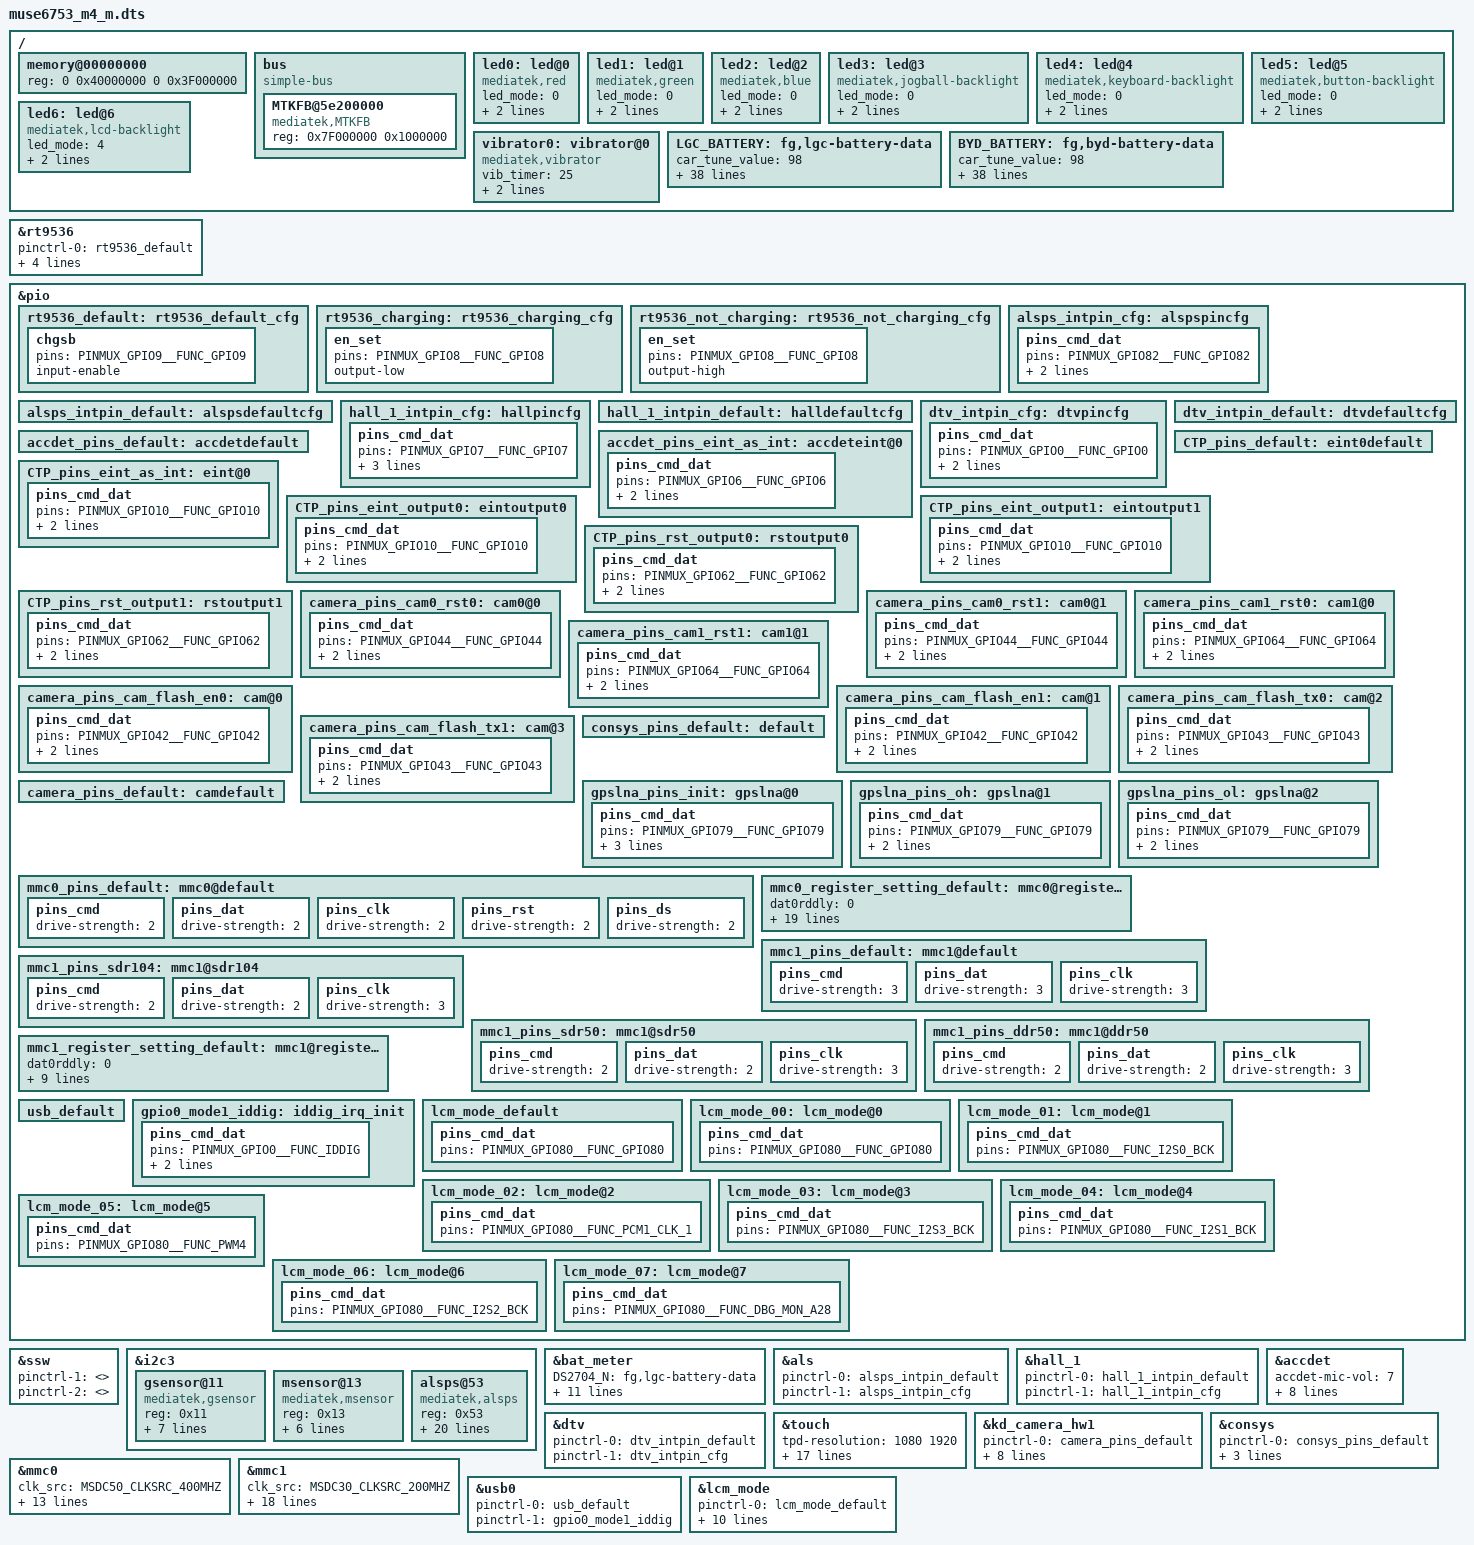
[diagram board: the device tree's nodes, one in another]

/dts-v1/;

#include "mt6753.dtsi"
#include <dt-bindings/lcm/r63417_fhd_dsi_cmd_truly_nt50358.dtsi>

/ {
memory@00000000 {
		device_type = "memory";
		reg = <0 0x40000000 0 0x3F000000>;
	};

	bus {
		compatible = "simple-bus";
		#address-cells = <1>;
		#size-cells = <1>;
		ranges = <0 0 0 0xffffffff>;

		MTKFB@5e200000 {
			compatible = "mediatek,MTKFB";
			reg = <0x7F000000 0x1000000>;
		};

	};
	led0:led@0 {
		compatible = "mediatek,red";
		led_mode = <0>;
		data = <1>;
		pwm_config = <0 0 0 0 0>;
	};
	led1:led@1 {
		compatible = "mediatek,green";
		led_mode = <0>;
		data = <1>;
		pwm_config = <0 0 0 0 0>;
	};
	led2:led@2 {
		compatible = "mediatek,blue";
		led_mode = <0>;
		data = <1>;
		pwm_config = <0 0 0 0 0>;
	};
	led3:led@3 {
		compatible = "mediatek,jogball-backlight";
		led_mode = <0>;
		data = <1>;
		pwm_config = <0 0 0 0 0>;
	};
	led4:led@4 {
		compatible = "mediatek,keyboard-backlight";
		led_mode = <0>;
		data = <1>;
		pwm_config = <0 0 0 0 0>;
	};
	led5:led@5 {
		compatible = "mediatek,button-backlight";
		led_mode = <0>;
		data = <1>;
		pwm_config = <0 0 0 0 0>;
	};
	led6:led@6 {
		compatible = "mediatek,lcd-backlight";
		led_mode = <4>;
		data = <1>;
		pwm_config = <0 0 0 0 0>;
	};
	vibrator0:vibrator@0 {
		compatible = "mediatek,vibrator";
		vib_timer = <25>;
		vib_limit = <9>;
		vib_vol= <6>;
	};
};

/* charger ic */
&rt9536 {
	status = "okay";
	pinctrl-names = "default", "charging", "not_charging";
	pinctrl-0 = <&rt9536_default>;
	pinctrl-1 = <&rt9536_charging>;
	pinctrl-2 = <&rt9536_not_charging>;
	en_set = <8>;
	chgsb = <9>;
};
&pio {
	rt9536_default: rt9536_default_cfg {
		chgsb {
			pins = <PINMUX_GPIO9__FUNC_GPIO9>;
			input-enable;
		};
	};

	rt9536_charging: rt9536_charging_cfg {
		en_set {
			pins = <PINMUX_GPIO8__FUNC_GPIO8>;
			output-low;
		};
	};
	rt9536_not_charging: rt9536_not_charging_cfg {
		en_set {
			pins = <PINMUX_GPIO8__FUNC_GPIO8>;
			output-high;
		};
	};
};

&ssw {
	pinctrl-1 = <>;
	pinctrl-2 = <>;
};
/* sensor standardization */
 &i2c3 {
	#address-cells = <1>;
	#size-cells = <0>;
	gsensor@11 {
		compatible = "mediatek,gsensor";
		reg = <0x11>;
		status = "okay";
		i2c_num				= <3>;
		i2c_addr				= <0x11 0 0 0>;
		direction				= <0>;
		power_id				= <0xffff>;
		power_vol				= <0>;
		firlen					= <0>;
		is_batch_supported			= <0>;
	};
	msensor@13 {
		compatible = "mediatek,msensor";
		reg = <0x13>;
		status = "okay";
		i2c_num				= <3>;
		i2c_addr				= <0x13 0 0 0>;
		direction				= <0>;
		power_id				= <0xffff>;
		power_vol				= <0>;
		is_batch_supported	= <0>;
	};
	alsps@53 {
		compatible = "mediatek,alsps";
		reg = <0x53>;
		status = "okay";
		i2c_num				= <3>;
		i2c_addr				= <0x53 0 0 0>;
		polling_mode_ps			= <0>;
		polling_mode_als		= <0>;
		power_id				= <0xffff>;
		power_vol				= <0>;
		als_level = <0 328 861 1377 3125 7721 7767 12621 23062 28430 33274 47116 57694 57694 65535>;
		als_value = <0 133 304 502 1004 2005 3058 5005 8008 10010 12000 16000 20000 20000 20000 20000>;
		near_offset		=  <200>;
		far_offset		=  <85>;
		crosstalk_max		=  <500>;
		ppcount			=  <50>;
		ps_led_current	=	<6>;/* 4:50mA  5:75mA  6:100mA */
		als_up_thres	=	<19>;
		als_low_thres	=	<15>;
		als_gain	=	<3>;
		is_batch_supported_ps	= <0>;
		is_batch_supported_als	= <0>;
	};
};

/* fuel gauge */
&bat_meter {
	    DS2704_N = "fg,lgc-battery-data";
		DS2704_L = "fg,lgc-battery-data";
		DS2704_C = "fg,lgc-battery-data";
		ISL6296_N = "fg,lgc-battery-data";
		ISL6296_L = "fg,lgc-battery-data";
		ISL6296_C = "fg,lgc-battery-data";
		RA4301_VC0 = "fg,byd-battery-data";
		RA4301_VC1 = "fg,lgc-battery-data";
		RA4301_VC2 = "fg,byd-battery-data";
		SW3800_VC0 = "fg,lgc-battery-data";
		SW3800_VC1 = "fg,byd-battery-data";
		SW3800_VC2 = "fg,lgc-battery-data";
};

/ {
	/* LGC 2300mA Battery 3.2V cut off */
	LGC_BATTERY: fg,lgc-battery-data {
		car_tune_value = <98 >;
		/* Qmax for 0mA */
		q_max_pos_50 = <2306 >;
		q_max_pos_25 = <2228 >;
		q_max_pos_0 = <1821 >;
		q_max_neg_10 = <1509 >;
		/* Qmax for 400mA, said high current */
		q_max_pos_50_h_current = <2286 >;
		q_max_pos_25_h_current = <2222 >;
		q_max_pos_0_h_current = <1792 >;
		q_max_neg_10_h_current = <1151>;

		battery_profile_t0_num = <92 >;
		battery_profile_t0 = <
			0 4306 	2 4285 	4 4267 	6 4249 	8 4232
			10 4215 	12 4196 	14 4175 	16 4151 	18 4120
			20 4095 	22 4075 	24 4057 	26 4036 	28 4017
			30 3998 	32 3981 	34 3965 	36 3949 	38 3935
			40 3923 	42 3914 	44 3903 	46 3894 	48 3883
			50 3874 	52 3865 	54 3857 	56 3849 	58 3842
			60 3834 	62 3827 	64 3819 	66 3811 	68 3804
			70 3794 	72 3785 	74 3776 	76 3766 	78 3756
			80 3746 	82 3738 	83 3730 	85 3724 	87 3718
			89 3712 	91 3707 	92 3703 	93 3699 	93 3696
			94 3694 	94 3690 	95 3687 	95 3685 	96 3682
			96 3680 	96 3678 	97 3677 	97 3674 	97 3672
			97 3671 	98 3669 	98 3666 	98 3665 	98 3663
			98 3661 	99 3659 	99 3658 	99 3656 	99 3655
			99 3653 	99 3652 	99 3650 	99 3649 	99 3648
			99 3647 	99 3645 	99 3645 	100 3643 	100 3642
			100 3640 	100 3639 	100 3638 	100 3637 	100 3636
			100 3634 	100 3634 	100 3633 	100 3632 	100 3632
			100 3630 	100 3300 >;

		battery_profile_t1_num = <92 >;
		battery_profile_t1 = <
			0 4326 	2 4297 	3 4257 	5 4228 	7 4209
			8 4191 	10 4176 	12 4160 	13 4145 	15 4130
			16 4116 	18 4101 	20 4088 	21 4077 	23 4063
			25 4046 	26 4028 	28 4010 	30 3992 	31 3975
			33 3959 	35 3945 	36 3932 	38 3922 	40 3912
			41 3903 	43 3893 	44 3885 	46 3875 	48 3867
			49 3860 	51 3852 	53 3845 	54 3838 	56 3832
			58 3825 	59 3819 	61 3813 	63 3807 	64 3802
			66 3795 	67 3789 	69 3782 	71 3775 	72 3768
			74 3760 	76 3754 	77 3746 	79 3738 	81 3730
			82 3721 	84 3714 	86 3708 	87 3704 	89 3701
			90 3696 	92 3689 	94 3674 	95 3644 	97 3590
			98 3550 	99 3523 	99 3505 	99 3493 	99 3483
			99 3476 	99 3470 	100 3466 	100 3462 	100 3459
			100 3456 	100 3455 	100 3452 	100 3452 	100 3451
			100 3450 	100 3449 	100 3447 	100 3446 	100 3444
			100 3443 	100 3442 	100 3441 	100 3440 	100 3439
			100 3437 	100 3435 	100 3435 	100 3433 	100 3432
			100 3432 	100 3300 >;

		battery_profile_t2_num = <92 >;
		battery_profile_t2 = <
			0 4334 	1 4310 	3 4291 	4 4274 	5 4258
			7 4242 	8 4227 	9 4212 	11 4196 	12 4181
			13 4167 	15 4153 	16 4139 	18 4125 	19 4111
			20 4097 	22 4084 	23 4073 	24 4066 	26 4054
			27 4033 	28 4011 	30 3996 	31 3987 	32 3981
			34 3974 	35 3964 	36 3954 	38 3943 	39 3932
			40 3919 	42 3906 	43 3891 	44 3879 	46 3869
			47 3860 	48 3852 	50 3844 	51 3837 	53 3831
			54 3825 	55 3820 	57 3815 	58 3810 	59 3805
			61 3801 	62 3797 	63 3793 	65 3789 	66 3786
			67 3782 	69 3778 	70 3775 	71 3771 	73 3767
			74 3762 	75 3757 	77 3751 	78 3747 	79 3742
			81 3736 	82 3728 	83 3720 	85 3712 	86 3701
			87 3693 	89 3691 	90 3689 	92 3688 	93 3685
			94 3670 	96 3620 	97 3548 	98 3443 	100 3249
			100 3048 	100 2984 	100 2957 	100 2946 	100 2934
			100 2928 	100 2922 	100 2919 	100 2916 	100 2912
			100 2912 	100 2912 	100 2912 	100 2912 	100 2912
			100 2912 	100 2912 >;

		battery_profile_t3_num = <92 >;
		battery_profile_t3 = <
			0 4339 	1 4318 	3 4299 	4 4282 	5 4265
			7 4249 	8 4234 	9 4217 	10 4203 	12 4186
			13 4172 	14 4157 	16 4142 	17 4128 	18 4115
			20 4101 	21 4087 	22 4074 	23 4062 	25 4049
			26 4035 	27 4022 	29 4009 	30 3997 	31 3987
			32 3978 	34 3967 	35 3957 	36 3947 	38 3938
			39 3927 	40 3916 	42 3905 	43 3890 	44 3878
			45 3865 	47 3855 	48 3846 	49 3839 	51 3832
			52 3825 	53 3820 	55 3814 	56 3809 	57 3804
			58 3799 	60 3795 	61 3791 	62 3787 	64 3784
			65 3781 	66 3778 	68 3775 	69 3771 	70 3769
			71 3765 	73 3761 	74 3756 	75 3751 	77 3746
			78 3740 	79 3736 	81 3731 	82 3721 	83 3712
			84 3703 	86 3692 	87 3682 	88 3679 	90 3675
			91 3671 	92 3665 	93 3649 	95 3602 	96 3533
			97 3434 	98 3316 	100 3291 	100 3279 	100 3273
			100 3268 	100 3264 	100 3264 	100 3262 	100 3259
			100 3257 	100 3258 	100 3260 	100 3261 	100 3261
			100 3261 	100 3261 >;

		battery_profile_temperature_num = <92 >;
		battery_profile_temperature = <
			0 0 	0 0 	0 0 	0 0 	0 0
			0 0 	0 0 	0 0 	0 0 	0 0
			0 0 	0 0 	0 0 	0 0 	0 0
			0 0 	0 0 	0 0 	0 0 	0 0
			0 0 	0 0 	0 0 	0 0 	0 0
			0 0 	0 0 	0 0 	0 0 	0 0
			0 0 	0 0 	0 0 	0 0 	0 0
			0 0 	0 0 	0 0 	0 0 	0 0
			0 0 	0 0 	0 0 	0 0 	0 0
			0 0 	0 0 	0 0 	0 0 	0 0
			0 0 	0 0 	0 0 	0 0 	0 0
			0 0 	0 0 	0 0 	0 0 	0 0
			0 0 	0 0 	0 0 	0 0 	0 0
			0 0 	0 0 	0 0 	0 0 	0 0
			0 0 	0 0 	0 0 	0 0 	0 0
			0 0 	0 0 	0 0 	0 0 	0 0
			0 0 	0 0 	0 0 	0 0 	0 0
			0 0 	0 0 	0 0 	0 0 	0 0
			0 0 	0 0 >;

		r_profile_t0_num = <92 >;
		r_profile_t0 = <
			638 4306 	638 4285 	660 4267 	670 4249 	683 4232
			698 4215 	708 4196 	725 4175 	748 4151 	825 4120
			933 4095 	988 4075 	1030 4057 	1043 4036 	1048 4017
			1050 3998 	1048 3981 	1048 3965 	1040 3949 	1038 3935
			1043 3923 	1048 3914 	1055 3903 	1063 3894 	1063 3883
			1070 3874 	1073 3865 	1083 3857 	1088 3849 	1098 3842
			1105 3834 	1113 3827 	1118 3819 	1125 3811 	1133 3804
			1138 3794 	1145 3785 	1153 3776 	1158 3766 	1165 3756
			1173 3746 	1188 3738 	1208 3730 	1233 3724 	1260 3718
			1283 3712 	1270 3707 	1258 3703 	1248 3699 	1240 3696
			1235 3694 	1225 3690 	1220 3687 	1213 3685 	1205 3682
			1200 3680 	1195 3678 	1193 3677 	1188 3674 	1183 3672
			1178 3671 	1175 3669 	1168 3666 	1165 3665 	1160 3663
			1155 3661 	1148 3659 	1148 3658 	1145 3656 	1143 3655
			1138 3653 	1138 3652 	1128 3650 	1125 3649 	1123 3648
			1118 3647 	1115 3645 	1118 3645 	1113 3643 	1110 3642
			1108 3640 	1103 3639 	1103 3638 	1098 3637 	1098 3636
			1098 3634 	1090 3634 	1090 3633 	1093 3632 	1090 3632
			1075 3630 	510 3300 >;

		r_profile_t1_num = <92 >;
		r_profile_t1 = <
			353 4326 	353 4297 	383 4257 	443 4228 	463 4209
			470 4191 	478 4176 	485 4160 	493 4145 	498 4130
			505 4116 	505 4101 	510 4088 	525 4077 	545 4063
			553 4046 	550 4028 	543 4010 	533 3992 	523 3975
			510 3959 	505 3945 	498 3932 	500 3922 	503 3912
			505 3903 	508 3893 	513 3885 	513 3875 	515 3867
			518 3860 	523 3852 	530 3845 	533 3838 	538 3832
			538 3825 	545 3819 	550 3813 	555 3807 	560 3802
			563 3795 	568 3789 	570 3782 	573 3775 	580 3768
			583 3760 	595 3754 	598 3746 	610 3738 	618 3730
			628 3721 	638 3714 	655 3708 	680 3704 	713 3701
			750 3696 	800 3689 	855 3674 	893 3644 	923 3590
			875 3550 	808 3523 	765 3505 	733 3493 	710 3483
			695 3476 	678 3470 	665 3466 	655 3462 	650 3459
			643 3456 	643 3455 	640 3452 	635 3452 	633 3451
			630 3450 	630 3449 	623 3447 	618 3446 	625 3444
			613 3443 	618 3442 	610 3441 	618 3440 	620 3439
			620 3437 	623 3435 	615 3435 	613 3433 	593 3432
			583 3432 	500 3300 >;

		r_profile_t2_num = <92 >;
		r_profile_t2 = <
			170 4334 	170 4310 	170 4291 	170 4274 	173 4258
			173 4242 	175 4227 	173 4212 	175 4196 	173 4181
			175 4167 	178 4153 	180 4139 	183 4125 	183 4111
			183 4097 	188 4084 	190 4073 	198 4066 	200 4054
			198 4033 	198 4011 	198 3996 	203 3987 	210 3981
			210 3974 	213 3964 	213 3954 	215 3943 	215 3932
			208 3919 	203 3906 	190 3891 	185 3879 	180 3869
			178 3860 	178 3852 	175 3844 	175 3837 	175 3831
			175 3825 	178 3820 	180 3815 	180 3810 	180 3805
			183 3801 	185 3797 	183 3793 	185 3789 	188 3786
			185 3782 	188 3778 	188 3775 	188 3771 	188 3767
			185 3762 	180 3757 	180 3751 	183 3747 	185 3742
			188 3736 	185 3728 	188 3720 	190 3712 	185 3701
			178 3693 	180 3691 	185 3689 	195 3688 	208 3685
			218 3670 	208 3620 	220 3548 	243 3443 	320 3249
			630 3048 	470 2984 	415 2957 	378 2946 	385 2934
			335 2928 	360 2922 	313 2919 	303 2916 	313 2912
			313 2912 	313 2912 	313 2912 	313 2912 	313 2912
			313 2912 	313 2912 >;

		r_profile_t3_num = <92 >;
		r_profile_t3 = <
			143 4339 	143 4318 	143 4299 	145 4282 	140 4265
			143 4249 	145 4234 	143 4217 	145 4203 	143 4186
			145 4172 	145 4157 	145 4142 	148 4128 	160 4115
			165 4101 	170 4087 	170 4074 	175 4062 	178 4049
			175 4035 	183 4022 	183 4009 	183 3997 	188 3987
			195 3978 	195 3967 	200 3957 	200 3947 	203 3938
			203 3927 	200 3916 	198 3905 	185 3890 	175 3878
			165 3865 	160 3855 	155 3846 	155 3839 	158 3832
			153 3825 	155 3820 	155 3814 	158 3809 	158 3804
			158 3799 	158 3795 	160 3791 	163 3787 	163 3784
			168 3781 	178 3778 	178 3775 	173 3771 	178 3769
			175 3765 	173 3761 	173 3756 	173 3751 	178 3746
			178 3740 	183 3736 	193 3731 	193 3721 	195 3712
			200 3703 	203 3692 	200 3682 	205 3679 	210 3675
			213 3671 	218 3665 	225 3649 	223 3602 	235 3533
			260 3434 	295 3316 	233 3291 	200 3279 	183 3273
			173 3268 	160 3264 	163 3264 	160 3262 	155 3259
			150 3257 	150 3258 	155 3260 	168 3261 	175 3261
			168 3261 	185 3261 >;

		r_profile_temperature_num = <92 >;
		r_profile_temperature = <
			0 0 	0 0 	0 0 	0 0 	0 0
			0 0 	0 0 	0 0 	0 0 	0 0
			0 0 	0 0 	0 0 	0 0 	0 0
			0 0 	0 0 	0 0 	0 0 	0 0
			0 0 	0 0 	0 0 	0 0 	0 0
			0 0 	0 0 	0 0 	0 0 	0 0
			0 0 	0 0 	0 0 	0 0 	0 0
			0 0 	0 0 	0 0 	0 0 	0 0
			0 0 	0 0 	0 0 	0 0 	0 0
			0 0 	0 0 	0 0 	0 0 	0 0
			0 0 	0 0 	0 0 	0 0 	0 0
			0 0 	0 0 	0 0 	0 0 	0 0
			0 0 	0 0 	0 0 	0 0 	0 0
			0 0 	0 0 	0 0 	0 0 	0 0
			0 0 	0 0 	0 0 	0 0 	0 0
			0 0 	0 0 	0 0 	0 0 	0 0
			0 0 	0 0 	0 0 	0 0 	0 0
			0 0 	0 0 	0 0 	0 0 	0 0
			0 0 	0 0 >;
	};

	/* BYD 2300mA Battery 3.3V cut off */
	BYD_BATTERY: fg,byd-battery-data {
		car_tune_value = <98 >;
		/* Qmax for 0mA */
		q_max_pos_50 = <2321 >;
		q_max_pos_25 = <2280 >;
		q_max_pos_0 = <2009 >;
		q_max_neg_10 = <1583 >;
		/* Qmax for 400mA, said high current */
		q_max_pos_50_h_current = <2294 >;
		q_max_pos_25_h_current = <2238 >;
		q_max_pos_0_h_current = <1674 >;
		q_max_neg_10_h_current = <1204 >;

		battery_profile_t0_num = <92 >;
		battery_profile_t0 = <
			0 4297 	2 4270 	4 4246 	6 4221 	8 4188
			9 4151 	11 4125 	13 4107 	15 4095 	17 4081
			19 4065 	21 4047 	23 4028 	25 4010 	26 3994
			28 3980 	30 3967 	32 3956 	34 3945 	36 3932
			38 3918 	40 3904 	42 3891 	44 3878 	45 3867
			47 3856 	49 3847 	51 3838 	53 3831 	55 3824
			57 3818 	59 3812 	61 3806 	63 3802 	64 3799
			66 3798 	68 3795 	70 3793 	72 3792 	74 3790
			76 3789 	78 3786 	80 3784 	81 3781 	83 3779
			84 3777 	85 3775 	86 3775 	87 3773 	88 3772
			88 3771 	89 3769 	89 3768 	90 3768 	90 3767
			91 3765 	91 3764 	92 3763 	92 3762 	93 3761
			93 3760 	93 3759 	94 3758 	94 3757 	94 3756
			95 3754 	95 3753 	95 3752 	95 3751 	96 3750
			96 3748 	96 3748 	96 3746 	97 3745 	97 3744
			97 3743 	97 3741 	98 3740 	98 3739 	98 3738
			98 3737 	98 3736 	99 3734 	99 3733 	99 3733
			99 3731 	99 3731 	99 3730 	100 3729 	100 3728
			100 3728 	100 3300 >;

		battery_profile_t1_num = <92 >;
		battery_profile_t1 = <
			0 4294 	1 4258 	3 4235 	4 4218 	6 4200
			7 4184 	9 4169 	10 4155 	12 4139 	13 4125
			15 4111 	16 4097 	18 4086 	19 4074 	21 4060
			22 4044 	24 4028 	25 4011 	27 3997 	28 3984
			30 3973 	31 3962 	33 3951 	34 3939 	36 3925
			37 3911 	39 3898 	40 3886 	42 3874 	43 3863
			45 3855 	46 3846 	48 3839 	49 3832 	51 3825
			52 3819 	54 3813 	55 3808 	57 3803 	58 3798
			60 3794 	61 3790 	63 3788 	64 3787 	66 3785
			67 3784 	69 3782 	70 3780 	72 3778 	73 3776
			75 3772 	76 3768 	78 3764 	79 3758 	81 3751
			82 3743 	84 3733 	85 3724 	87 3713 	88 3704
			89 3697 	90 3694 	91 3692 	92 3691 	93 3689
			93 3688 	94 3687 	94 3686 	95 3686 	95 3685
			95 3684 	96 3683 	96 3682 	96 3681 	97 3680
			97 3679 	97 3677 	98 3675 	98 3673 	98 3670
			98 3668 	98 3664 	99 3660 	99 3656 	99 3652
			99 3647 	99 3642 	100 3636 	100 3631 	100 3627
			100 3621 	100 3300 >;

		battery_profile_t2_num = <92 >;
		battery_profile_t2 = <
			0 4335 	1 4315 	3 4297 	4 4280 	5 4265
			7 4249 	8 4233 	9 4218 	10 4204 	12 4189
			13 4174 	14 4159 	16 4145 	17 4131 	18 4118
			20 4104 	21 4090 	22 4078 	24 4067 	25 4054
			26 4040 	28 4026 	29 4013 	30 4001 	31 3991
			33 3980 	34 3972 	35 3962 	37 3952 	38 3943
			39 3933 	41 3924 	42 3913 	43 3900 	45 3883
			46 3869 	47 3858 	48 3848 	50 3840 	51 3833
			52 3827 	54 3822 	55 3816 	56 3811 	58 3806
			59 3802 	60 3798 	62 3794 	63 3790 	64 3786
			65 3783 	67 3780 	68 3777 	69 3775 	71 3773
			72 3771 	73 3769 	75 3766 	76 3763 	77 3759
			79 3752 	80 3745 	81 3740 	82 3733 	84 3723
			85 3712 	86 3701 	88 3687 	89 3683 	90 3681
			92 3678 	93 3675 	94 3671 	96 3656 	97 3605
			98 3522 	99 3394 	100 3213 	100 3150 	100 3108
			100 3074 	100 3047 	100 3025 	100 3009 	100 2996
			100 2996 	100 2996 	100 2996 	100 2996 	100 2996
			100 2996 	100 2996 >;

		battery_profile_t3_num = <92 >;
		battery_profile_t3 = <
			0 4338 	1 4317 	3 4299 	4 4283 	5 4266
			6 4250 	8 4235 	9 4219 	10 4205 	12 4190
			13 4174 	14 4160 	16 4146 	17 4132 	18 4118
			19 4105 	21 4092 	22 4078 	23 4067 	25 4054
			26 4041 	27 4027 	28 4014 	30 4001 	31 3991
			32 3981 	34 3972 	35 3962 	36 3952 	37 3943
			39 3934 	40 3924 	41 3914 	43 3903 	44 3891
			45 3876 	46 3862 	48 3851 	49 3842 	50 3834
			52 3828 	53 3821 	54 3816 	55 3810 	57 3806
			58 3802 	59 3797 	61 3793 	62 3789 	63 3786
			65 3783 	66 3781 	67 3778 	68 3774 	70 3772
			71 3770 	72 3767 	74 3765 	75 3762 	76 3758
			77 3754 	79 3748 	80 3742 	81 3736 	83 3729
			84 3719 	85 3708 	86 3696 	88 3682 	89 3679
			90 3676 	92 3674 	93 3670 	94 3665 	95 3648
			97 3595 	98 3512 	99 3386 	100 3327 	100 3302
			100 3289 	100 3281 	100 3275 	100 3271 	100 3267
			100 3267 	100 3269 	100 3271 	100 3272 	100 3272
			100 3272 	100 3272 >;

		battery_profile_temperature_num = <92 >;
		battery_profile_temperature = <
			0 0 	0 0 	0 0 	0 0 	0 0
			0 0 	0 0 	0 0 	0 0 	0 0
			0 0 	0 0 	0 0 	0 0 	0 0
			0 0 	0 0 	0 0 	0 0 	0 0
			0 0 	0 0 	0 0 	0 0 	0 0
			0 0 	0 0 	0 0 	0 0 	0 0
			0 0 	0 0 	0 0 	0 0 	0 0
			0 0 	0 0 	0 0 	0 0 	0 0
			0 0 	0 0 	0 0 	0 0 	0 0
			0 0 	0 0 	0 0 	0 0 	0 0
			0 0 	0 0 	0 0 	0 0 	0 0
			0 0 	0 0 	0 0 	0 0 	0 0
			0 0 	0 0 	0 0 	0 0 	0 0
			0 0 	0 0 	0 0 	0 0 	0 0
			0 0 	0 0 	0 0 	0 0 	0 0
			0 0 	0 0 	0 0 	0 0 	0 0
			0 0 	0 0 	0 0 	0 0 	0 0
			0 0 	0 0 	0 0 	0 0 	0 0
			0 0 	0 0 >;

		r_profile_t0_num = <92 >;
		r_profile_t0 = <
			880 4297 	880 4270 	895 4246 	908 4221 	920 4188
			970 4151 	1020 4125 	1038 4107 	1065 4095 	1085 4081
			1093 4065 	1090 4047 	1083 4028 	1078 4010 	1073 3994
			1073 3980 	1075 3967 	1078 3956 	1090 3945 	1088 3932
			1080 3918 	1083 3904 	1078 3891 	1073 3878 	1075 3867
			1075 3856 	1078 3847 	1083 3838 	1085 3831 	1095 3824
			1103 3818 	1110 3812 	1120 3806 	1133 3802 	1153 3799
			1178 3798 	1200 3795 	1225 3793 	1255 3792 	1283 3790
			1320 3789 	1355 3786 	1398 3784 	1438 3781 	1450 3779
			1443 3777 	1440 3775 	1438 3775 	1435 3773 	1433 3772
			1428 3771 	1425 3769 	1420 3768 	1420 3768 	1420 3767
			1415 3765 	1413 3764 	1408 3763 	1408 3762 	1405 3761
			1400 3760 	1400 3759 	1398 3758 	1393 3757 	1390 3756
			1388 3754 	1383 3753 	1380 3752 	1383 3751 	1378 3750
			1373 3748 	1375 3748 	1368 3746 	1365 3745 	1360 3744
			1363 3743 	1358 3741 	1355 3740 	1353 3739 	1350 3738
			1343 3737 	1345 3736 	1335 3734 	1338 3733 	1333 3733
			1330 3731 	1333 3731 	1330 3730 	1328 3729 	1325 3728
			1325 3728 	500 3300 >;

		r_profile_t1_num = <92 >;
		r_profile_t1 = <
			490 4294 	490 4258 	503 4235 	515 4218 	520 4200
			525 4184 	533 4169 	540 4155 	540 4139 	545 4125
			550 4111 	558 4097 	575 4086 	595 4074 	603 4060
			598 4044 	590 4028 	580 4011 	578 3997 	575 3984
			575 3973 	575 3962 	578 3951 	578 3939 	568 3925
			563 3911 	553 3898 	548 3886 	540 3874 	538 3863
			540 3855 	543 3846 	548 3839 	548 3832 	553 3825
			558 3819 	565 3813 	570 3808 	578 3803 	583 3798
			588 3794 	598 3790 	618 3788 	635 3787 	653 3785
			673 3784 	695 3782 	723 3780 	755 3778 	795 3776
			835 3772 	878 3768 	928 3764 	970 3758 	1018 3751
			1058 3743 	1095 3733 	1138 3724 	1178 3713 	1218 3704
			1245 3697 	1238 3694 	1230 3692 	1230 3691 	1223 3689
			1223 3688 	1220 3687 	1218 3686 	1215 3686 	1213 3685
			1210 3684 	1208 3683 	1210 3682 	1208 3681 	1203 3680
			1203 3679 	1200 3677 	1193 3675 	1185 3673 	1175 3670
			1173 3668 	1163 3664 	1153 3660 	1148 3656 	1138 3652
			1120 3647 	1110 3642 	1093 3636 	1083 3631 	1073 3627
			1063 3621 	508 3300 >;

		r_profile_t2_num = <92 >;
		r_profile_t2 = <
			185 4335 	185 4315 	183 4297 	183 4280 	183 4265
			185 4249 	183 4233 	180 4218 	185 4204 	185 4189
			188 4174 	188 4159 	190 4145 	190 4131 	193 4118
			195 4104 	193 4090 	198 4078 	200 4067 	205 4054
			208 4040 	208 4026 	210 4013 	213 4001 	218 3991
			218 3980 	228 3972 	228 3962 	230 3952 	235 3943
			240 3933 	240 3924 	238 3913 	230 3900 	215 3883
			203 3869 	195 3858 	193 3848 	190 3840 	188 3833
			190 3827 	193 3822 	190 3816 	190 3811 	190 3806
			195 3802 	198 3798 	195 3794 	198 3790 	195 3786
			195 3783 	195 3780 	193 3777 	195 3775 	198 3773
			198 3771 	203 3769 	205 3766 	210 3763 	218 3759
			218 3752 	223 3745 	233 3740 	243 3733 	250 3723
			258 3712 	265 3701 	268 3687 	280 3683 	295 3681
			315 3678 	338 3675 	375 3671 	423 3656 	458 3605
			558 3522 	710 3394 	1040 3213 	875 3150 	790 3108
			718 3074 	643 3047 	588 3025 	548 3009 	533 2996
			518 2996 	518 2996 	518 2996 	518 2996 	518 2996
			518 2996 	518 2996 >;

		r_profile_t3_num = <92 >;
		r_profile_t3 = <
			143 4338 	143 4317 	143 4299 	143 4283 	140 4266
			140 4250 	143 4235 	140 4219 	143 4205 	145 4190
			143 4174 	145 4160 	148 4146 	158 4132 	168 4118
			173 4105 	178 4092 	178 4078 	183 4067 	185 4054
			188 4041 	188 4027 	193 4014 	195 4001 	198 3991
			203 3981 	208 3972 	210 3962 	210 3952 	215 3943
			218 3934 	218 3924 	218 3914 	210 3903 	200 3891
			183 3876 	168 3862 	160 3851 	158 3842 	153 3834
			155 3828 	153 3821 	155 3816 	153 3810 	155 3806
			158 3802 	158 3797 	158 3793 	160 3789 	163 3786
			173 3783 	175 3781 	175 3778 	170 3774 	170 3772
			170 3770 	170 3767 	170 3765 	175 3762 	175 3758
			178 3754 	183 3748 	190 3742 	193 3736 	200 3729
			208 3719 	213 3708 	220 3696 	215 3682 	213 3679
			213 3676 	220 3674 	228 3670 	235 3665 	245 3648
			260 3595 	293 3512 	370 3386 	320 3327 	260 3302
			225 3289 	203 3281 	190 3275 	183 3271 	175 3267
			170 3267 	175 3269 	185 3271 	193 3272 	200 3272
			195 3272 	183 3272 >;

		r_profile_temperature_num = <92 >;
		r_profile_temperature = <
			0 0 	0 0 	0 0 	0 0 	0 0
			0 0 	0 0 	0 0 	0 0 	0 0
			0 0 	0 0 	0 0 	0 0 	0 0
			0 0 	0 0 	0 0 	0 0 	0 0
			0 0 	0 0 	0 0 	0 0 	0 0
			0 0 	0 0 	0 0 	0 0 	0 0
			0 0 	0 0 	0 0 	0 0 	0 0
			0 0 	0 0 	0 0 	0 0 	0 0
			0 0 	0 0 	0 0 	0 0 	0 0
			0 0 	0 0 	0 0 	0 0 	0 0
			0 0 	0 0 	0 0 	0 0 	0 0
			0 0 	0 0 	0 0 	0 0 	0 0
			0 0 	0 0 	0 0 	0 0 	0 0
			0 0 	0 0 	0 0 	0 0 	0 0
			0 0 	0 0 	0 0 	0 0 	0 0
			0 0 	0 0 	0 0 	0 0 	0 0
			0 0 	0 0 	0 0 	0 0 	0 0
			0 0 	0 0 	0 0 	0 0 	0 0
			0 0 	0 0 >;
	};
};

/* sensor gpio standization */
&als {
	pinctrl-names = "pin_default", "pin_cfg";
	pinctrl-0 = <&alsps_intpin_default>;
	pinctrl-1 = <&alsps_intpin_cfg>;
	status = "okay";
};

&pio {
	alsps_intpin_cfg: alspspincfg {

	    pins_cmd_dat {
			pins = <PINMUX_GPIO82__FUNC_GPIO82>;
			slew-rate = <0>;
			bias-pull-up = <00>;
		};
	};

	alsps_intpin_default: alspsdefaultcfg {

	};
};
&hall_1 {
	pinctrl-names = "pin_default", "pin_cfg";
	pinctrl-0 = <&hall_1_intpin_default>;
	pinctrl-1 = <&hall_1_intpin_cfg>;
	status = "okay";
};

&pio {
	hall_1_intpin_cfg: hallpincfg {

	    pins_cmd_dat {
			pins = <PINMUX_GPIO7__FUNC_GPIO7>;
			slew-rate = <0>;
			bias-disable;
			input-enable;
		};
	};

	hall_1_intpin_default: halldefaultcfg {

	};
};
/* sensor end */

/* dtv gpio standization */
&dtv {
	pinctrl-names = "pin_default", "pin_cfg";
	pinctrl-0 = <&dtv_intpin_default>;
	pinctrl-1 = <&dtv_intpin_cfg>;
	status = "okay";
};

&pio {
	dtv_intpin_cfg: dtvpincfg {
		pins_cmd_dat {
			pins = <PINMUX_GPIO0__FUNC_GPIO0>;
			slew-rate = <0>;
			bias-pull-down = <00>;
		};
	};

	dtv_intpin_default: dtvdefaultcfg {

	};
};
/* dtv end */

&accdet {
	accdet-mic-vol = <7>;
	headset-mode-setting = <0x500 0x500 1 0x1f0 0x800 0x800 0x20>;
	accdet-plugout-debounce = <20>;
	/*1:ACC mode, 2:low cost without in bias, 6:low cost with in bias*/
	accdet-mic-mode = <1>;
	/*0--MD_MAX--UP_MAX--DW_MAX*/
	headset-three-key-threshold = <0 80 180 500>;
	/*0--MD_MAX--VOICE_MAX--UP_MAX--DW_MAX*/
	headset-four-key-threshold = <0 80 105 180 500>;
	/* ACCDET GPIO standardization ACC mode use */
	pinctrl-names = "default", "state_eint_as_int";
	pinctrl-0 = <&accdet_pins_default>;
	pinctrl-1 = <&accdet_pins_eint_as_int>;
	status = "okay";
};
&pio {
	accdet_pins_default: accdetdefault {
	};
	accdet_pins_eint_as_int: accdeteint@0 {
		pins_cmd_dat {
			pins = <PINMUX_GPIO6__FUNC_GPIO6>;
			slew-rate = <0>;
			bias-disable;
		};
	};
};
&touch {
	tpd-resolution = <1080 1920>;
	use-tpd-button = <0>;
	tpd-key-num = <3>;
	tpd-key-local= <139 172 158 0>;
	tpd-key-dim-local = <90 883 100 40 230 883 100 40 370 883 100 40 0 0 0 0>;
	tpd-max-touch-num = <5>;
	tpd-filter-enable = <1>;
	tpd-filter-pixel-density = <186>;
	tpd-filter-custom-prameters = <0 0 0 0 0 0 0 0 0 0 0 0>;
	tpd-filter-custom-speed = <0 0 0>;
	pinctrl-names = "default", "state_eint_as_int", "state_eint_output0", "state_eint_output1",
		"state_rst_output0", "state_rst_output1";
	pinctrl-0 = <&CTP_pins_default>;
	pinctrl-1 = <&CTP_pins_eint_as_int>;
	pinctrl-2 = <&CTP_pins_eint_output0>;
	pinctrl-3 = <&CTP_pins_eint_output1>;
	pinctrl-4 = <&CTP_pins_rst_output0>;
	pinctrl-5 = <&CTP_pins_rst_output1>;
	status = "okay";
};
&pio {
	CTP_pins_default: eint0default {
	};
	CTP_pins_eint_as_int: eint@0 {
		pins_cmd_dat {
			pins = <PINMUX_GPIO10__FUNC_GPIO10>;
			slew-rate = <0>;
			bias-disable;
		};
	};
	CTP_pins_eint_output0: eintoutput0 {
		pins_cmd_dat {
			pins = <PINMUX_GPIO10__FUNC_GPIO10>;
			slew-rate = <1>;
			output-low;
		};
	};
	CTP_pins_eint_output1: eintoutput1 {
		pins_cmd_dat {
			pins = <PINMUX_GPIO10__FUNC_GPIO10>;
			slew-rate = <1>;
			output-high;
		};
	};
	CTP_pins_rst_output0: rstoutput0 {
		pins_cmd_dat {
			pins = <PINMUX_GPIO62__FUNC_GPIO62>;
			slew-rate = <1>;
			output-low;
		};
	};
	CTP_pins_rst_output1: rstoutput1 {
		pins_cmd_dat {
			pins = <PINMUX_GPIO62__FUNC_GPIO62>;
			slew-rate = <1>;
			output-high;
		};
	};
};
/* TOUCH end */

/* CAMERA GPIO standardization */
&pio {
	camera_pins_cam0_rst0: cam0@0 {
		pins_cmd_dat {
			pins = <PINMUX_GPIO44__FUNC_GPIO44>;/*GPIO_CAMERA_CMRST_PIN*/
			slew-rate = <1>; /*direction 0:in, 1:out*/
			output-low;/*direction out used only. output_low or high*/
		};
	};
	camera_pins_cam0_rst1: cam0@1 {
		pins_cmd_dat {
			pins = <PINMUX_GPIO44__FUNC_GPIO44>;/*GPIO_CAMERA_CMRST_PIN*/
			slew-rate = <1>;
			output-high;
		};
	};
	camera_pins_cam1_rst0: cam1@0 {
	    pins_cmd_dat {
			pins = <PINMUX_GPIO64__FUNC_GPIO64>;/*GPIO_CAMERA_CMRST1_PIN*/
			slew-rate = <1>; /*direction 0:in, 1:out*/
			output-low;/*direction out used only. output_low or high*/
		};
	};
	camera_pins_cam1_rst1: cam1@1 {
	    pins_cmd_dat {
			pins = <PINMUX_GPIO64__FUNC_GPIO64>;/*GPIO_CAMERA_CMRST1_PIN*/
			slew-rate = <1>;
			output-high;
		};
	};
	camera_pins_cam_flash_en0: cam@0 {
	    pins_cmd_dat {
			pins = <PINMUX_GPIO42__FUNC_GPIO42>;/*GPIO_CAMERA_FLASH_EN_PIN*/
			slew-rate = <1>; /*direction 0:in, 1:out*/
			output-low;/*direction out used only. output_low or high*/
		};
	};
	camera_pins_cam_flash_en1: cam@1 {
	    pins_cmd_dat {
			pins = <PINMUX_GPIO42__FUNC_GPIO42>;/*GPIO_CAMERA_FLASH_EN_PIN*/
			slew-rate = <1>; /*direction 0:in, 1:out*/
			output-high;
		};
	};
	camera_pins_cam_flash_tx0: cam@2 {
	    pins_cmd_dat {
			pins = <PINMUX_GPIO43__FUNC_GPIO43>;/*GPIO_CAMERA_FLASH_TX_PIN*/
			slew-rate = <1>; /*direction 0:in, 1:out*/
			output-low;/*direction out used only. output_low or high*/
		};
	};
	camera_pins_cam_flash_tx1: cam@3 {
	    pins_cmd_dat {
			pins = <PINMUX_GPIO43__FUNC_GPIO43>;/*GPIO_CAMERA_FLASH_TX_PIN*/
			slew-rate = <1>; /*direction 0:in, 1:out*/
			output-high;/*direction out used only. output_low or high*/
		};
	};
	camera_pins_default: camdefault {
	};

};

&kd_camera_hw1 {
	pinctrl-names = "default", "cam0_rst0", "cam0_rst1", "cam1_rst0", "cam1_rst1",
		"cam_flash_en0", "cam_flash_en1", "cam_flash_tx0", "cam_flash_tx1";
	pinctrl-0 = <&camera_pins_default>;
	pinctrl-1 = <&camera_pins_cam0_rst0>;
	pinctrl-2 = <&camera_pins_cam0_rst1>;
	pinctrl-3 = <&camera_pins_cam1_rst0>;
	pinctrl-4 = <&camera_pins_cam1_rst1>;
	pinctrl-5 = <&camera_pins_cam_flash_en0>;
	pinctrl-6 = <&camera_pins_cam_flash_en1>;
	pinctrl-7 = <&camera_pins_cam_flash_tx0>;
	pinctrl-8 = <&camera_pins_cam_flash_tx1>;
	status = "okay";

};
/* CAMERA GPIO end */

/* CONSYS GPIO standardization */
&pio {
	consys_pins_default: default {

	};

	gpslna_pins_init: gpslna@0 {

	    pins_cmd_dat {
			pins = <PINMUX_GPIO79__FUNC_GPIO79>;
			slew-rate = <0>;
			bias-disable;
			output-low;
		};
	};

	gpslna_pins_oh: gpslna@1 {

	    pins_cmd_dat {
			pins = <PINMUX_GPIO79__FUNC_GPIO79>;
			slew-rate = <1>;
			output-high;
		};
	};

	gpslna_pins_ol: gpslna@2 {

	    pins_cmd_dat {
			pins = <PINMUX_GPIO79__FUNC_GPIO79>;
			slew-rate = <1>;
			output-low;
		};
	};

};

&consys {
	pinctrl-names = "default", "gps_lna_state_init", "gps_lna_state_oh", "gps_lna_state_ol";
	pinctrl-0 = <&consys_pins_default>;
	pinctrl-1 = <&gpslna_pins_init>;
	pinctrl-2 = <&gpslna_pins_oh>;
	pinctrl-3 = <&gpslna_pins_ol>;
	status = "okay";

};
/* CONSYS end */
/* mmc start */
&mmc0 {
		clk_src = /bits/ 8 <MSDC50_CLKSRC_400MHZ>;
		bus-width = <8>;
		max-frequency = <200000000>;
		cap-mmc-highspeed;
		msdc-sys-suspend;
		mmc-ddr-1_8v;
		mmc-hs200-1_8v;
		mmc-hs400-1_8v;
		non-removable;
		pinctl = <&mmc0_pins_default>;
		register_setting = <&mmc0_register_setting_default>;
		host_function = /bits/ 8 <MSDC_EMMC>;
		bootable;
		status = "okay";
};

&mmc1 {
		clk_src = /bits/ 8 <MSDC30_CLKSRC_200MHZ>;
		bus-width = <4>;
		max-frequency = <200000000>;
		msdc-sys-suspend;
		cap-sd-highspeed;
		sd-uhs-sdr12;
		sd-uhs-sdr25;
		sd-uhs-sdr50;
		sd-uhs-sdr104;
		sd-uhs-ddr50;
		pinctl = <&mmc1_pins_default>;
		pinctl_sdr104 = <&mmc1_pins_sdr104>;
		pinctl_sdr50 = <&mmc1_pins_sdr50>;
		pinctl_ddr50 = <&mmc1_pins_ddr50>;
		register_setting = <&mmc1_register_setting_default>;
		host_function = /bits/ 8 <MSDC_SD>;
		cd_level = /bits/ 8 <MSDC_CD_LOW>;
		cd-gpios = <&pio 5 0>;
		status = "okay";
};

&pio {
	mmc0_pins_default: mmc0@default {
			pins_cmd {
				drive-strength = /bits/ 8 <2>;
			};
			pins_dat {
				drive-strength = /bits/ 8 <2>;
			};
			pins_clk {
				drive-strength = /bits/ 8 <2>;
			};
			pins_rst {
				drive-strength = /bits/ 8 <2>;
			};
			pins_ds {
				drive-strength = /bits/ 8 <2>;
			};
	};

	mmc0_register_setting_default: mmc0@register_default {
		dat0rddly      = /bits/ 8 <0>;
		dat1rddly      = /bits/ 8 <0>;
		dat2rddly      = /bits/ 8 <0>;
		dat3rddly      = /bits/ 8 <0>;
		dat4rddly      = /bits/ 8 <0>;
		dat5rddly      = /bits/ 8 <0>;
		dat6rddly      = /bits/ 8 <0>;
		dat7rddly      = /bits/ 8 <0>;
		datwrddly      = /bits/ 8 <0>;
		cmdrrddly      = /bits/ 8 <0>;
		cmdrddly       = /bits/ 8 <0>;
		cmd_edge = /bits/ 8 <MSDC_SMPL_FALLING>;
		rdata_edge = /bits/ 8 <MSDC_SMPL_FALLING>;
		wdata_edge = /bits/ 8 <MSDC_SMPL_FALLING>;

		ett-hs200-cells = <12>;
		ett-hs200-default = <OFFSET_MSDC_PATCH_BIT0	MSDC_PB0_INT_DAT_LATCH_CK_SEL 0x0
			OFFSET_MSDC_PATCH_BIT0	MSDC_PB0_CKGEN_MSDC_DLY_SEL   0x0
			OFFSET_MSDC_PATCH_BIT1	MSDC_PB1_CMD_RSP_TA_CNTR      0x1
			OFFSET_MSDC_IOCON		MSDC_IOCON_RSPL               0x0
			OFFSET_MSDC_PAD_TUNE0	MSDC_PAD_TUNE0_CMDRDLY        0x7
			OFFSET_MSDC_PAD_TUNE0	MSDC_PAD_TUNE0_CMDRRDLY       0xb
			OFFSET_MSDC_PATCH_BIT1		MSDC_PB1_WRDAT_CRCS_TA_CNTR   0x1
			OFFSET_MSDC_PAD_TUNE0	MSDC_PAD_TUNE0_DATWRDLY       0xb
			OFFSET_MSDC_IOCON			MSDC_IOCON_W_D0SPL            0x0
			OFFSET_MSDC_DAT_RDDLY0		MSDC_DAT_RDDLY0_D0            0x7
			OFFSET_MSDC_PAD_TUNE0	MSDC_PAD_TUNE0_DATRRDLY       0x9
			OFFSET_MSDC_IOCON		MSDC_IOCON_R_D_SMPL           0x0>;

		ett-hs400-cells = <8>;
		ett-hs400-default = <OFFSET_MSDC_PATCH_BIT0	MSDC_PB0_INT_DAT_LATCH_CK_SEL	0x0
			OFFSET_MSDC_PATCH_BIT0		MSDC_PB0_CKGEN_MSDC_DLY_SEL		0x0
			OFFSET_EMMC50_PAD_DS_TUNE	MSDC_EMMC50_PAD_DS_TUNE_DLY1	0x2
			OFFSET_EMMC50_PAD_DS_TUNE	MSDC_EMMC50_PAD_DS_TUNE_DLY3	0x10
			OFFSET_MSDC_PATCH_BIT1			MSDC_PB1_CMD_RSP_TA_CNTR	0x1
			OFFSET_MSDC_IOCON		MSDC_IOCON_RSPL				0x0
			OFFSET_MSDC_PAD_TUNE0			MSDC_PAD_TUNE0_CMDRDLY		0x6
			OFFSET_MSDC_PAD_TUNE0		MSDC_PAD_TUNE0_CMDRRDLY		0x6>;
	};

	mmc1_pins_default: mmc1@default {
			pins_cmd {
				drive-strength = /bits/ 8 <3>;
			};
			pins_dat {
				drive-strength = /bits/ 8 <3>;
			};
			pins_clk {
				drive-strength = /bits/ 8 <3>;
			};
	};

	mmc1_pins_sdr104: mmc1@sdr104 {
			pins_cmd {
				drive-strength = /bits/ 8 <2>;
			};
			pins_dat {
				drive-strength = /bits/ 8 <2>;
			};
			pins_clk {
				drive-strength = /bits/ 8 <3>;
			};
	};

	mmc1_pins_sdr50: mmc1@sdr50 {
			pins_cmd {
				drive-strength = /bits/ 8 <2>;
			};
			pins_dat {
				drive-strength = /bits/ 8 <2>;
			};
			pins_clk {
				drive-strength = /bits/ 8 <3>;
			};
	};

	mmc1_pins_ddr50: mmc1@ddr50 {
			pins_cmd {
				drive-strength = /bits/ 8 <2>;
			};
			pins_dat {
				drive-strength = /bits/ 8 <2>;
			};
			pins_clk {
				drive-strength = /bits/ 8 <3>;
			};
	};

	mmc1_register_setting_default: mmc1@register_default {
				dat0rddly      = /bits/ 8 <0>;
				dat1rddly      = /bits/ 8 <0>;
				dat2rddly      = /bits/ 8 <0>;
				dat3rddly      = /bits/ 8 <0>;
				datwrddly      = /bits/ 8 <0>;
				cmdrrddly      = /bits/ 8 <0>;
				cmdrddly       = /bits/ 8 <0>;
				cmd_edge = /bits/ 8 <MSDC_SMPL_FALLING>;
				rdata_edge = /bits/ 8 <MSDC_SMPL_FALLING>;
				wdata_edge = /bits/ 8 <MSDC_SMPL_FALLING>;
	};
};
/* mmc end */

/* USB GPIO Kernal Standardization start */
&pio {
	usb_default: usb_default {
	};

	gpio0_mode1_iddig: iddig_irq_init {
		pins_cmd_dat {
			pins = <PINMUX_GPIO0__FUNC_IDDIG>;
			slew-rate = <0>;
			bias-pull-up = <00>;
		};
	};
};

&usb0 {
	pinctrl-names = "usb_default", "iddig_irq_init";
	pinctrl-0 = <&usb_default>;
	pinctrl-1 = <&gpio0_mode1_iddig>;
	status = "okay";
};
/* USB GPIO Kernal Standardization end */

/* LCM GPIO Kernal Standardization start */
&pio {
	lcm_mode_default: lcm_mode_default {
		pins_cmd_dat {
			pins = <PINMUX_GPIO80__FUNC_GPIO80>;
		};
	};

	lcm_mode_00: lcm_mode@0 {
		pins_cmd_dat {
			pins = <PINMUX_GPIO80__FUNC_GPIO80>;
		};
	};

	lcm_mode_01: lcm_mode@1 {
		pins_cmd_dat {
			pins = <PINMUX_GPIO80__FUNC_I2S0_BCK>;
		};
	};

	lcm_mode_02: lcm_mode@2 {
		pins_cmd_dat {
			pins = <PINMUX_GPIO80__FUNC_PCM1_CLK_1>;
		};
	};

	lcm_mode_03: lcm_mode@3 {
		pins_cmd_dat {
			pins = <PINMUX_GPIO80__FUNC_I2S3_BCK>;
		};
	};

	lcm_mode_04: lcm_mode@4 {
		pins_cmd_dat {
			pins = <PINMUX_GPIO80__FUNC_I2S1_BCK>;
		};
	};

	lcm_mode_05: lcm_mode@5 {
		pins_cmd_dat {
			pins = <PINMUX_GPIO80__FUNC_PWM4>;
		};
	};

	lcm_mode_06: lcm_mode@6 {
		pins_cmd_dat {
			pins = <PINMUX_GPIO80__FUNC_I2S2_BCK>;
		};
	};

	lcm_mode_07: lcm_mode@7 {
		pins_cmd_dat {
			pins = <PINMUX_GPIO80__FUNC_DBG_MON_A28>;
		};
	};
};

&lcm_mode {
	pinctrl-names = "default", "lcm_mode_00", "lcm_mode_01", "lcm_mode_02", "lcm_mode_03", "lcm_mode_04",
	 "lcm_mode_05", "lcm_mode_06", "lcm_mode_07";
	pinctrl-0 = <&lcm_mode_default>;
	pinctrl-1 = <&lcm_mode_00>;
	pinctrl-2 = <&lcm_mode_01>;
	pinctrl-3 = <&lcm_mode_02>;
	pinctrl-4 = <&lcm_mode_03>;
	pinctrl-5 = <&lcm_mode_04>;
	pinctrl-6 = <&lcm_mode_05>;
	pinctrl-7 = <&lcm_mode_06>;
	pinctrl-8 = <&lcm_mode_07>;
	lcm_power_gpio = <&pio 80 0>;
	lcm_bl_gpio = <&pio 129 0>;
	status = "okay";
};
/* LCM GPIO Kernal Standardization end */
